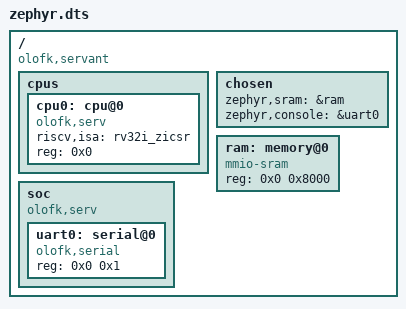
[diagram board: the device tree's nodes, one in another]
/dts-v1/;

/ {
	#address-cells = < 0x1 >;
	#size-cells = < 0x1 >;
	compatible = "olofk,servant";
	cpus {
		#address-cells = < 0x1 >;
		#size-cells = < 0x0 >;
		cpu0: cpu@0 {
			compatible = "olofk,serv";
			riscv,isa = "rv32i_zicsr";
			reg = < 0x0 >;
			device_type = "cpu";
		};
	};
	chosen {
		zephyr,sram = &ram;
		zephyr,console = &uart0;
	};
	ram: memory@0 {
		compatible = "mmio-sram";
		reg = < 0x0 0x8000 >;
	};
	soc {
		compatible = "olofk,serv";
		#address-cells = < 0x1 >;
		#size-cells = < 0x1 >;
		uart0: serial@0 {
			reg = < 0x0 0x1 >;
			compatible = "olofk,serial";
		};
	};
};
